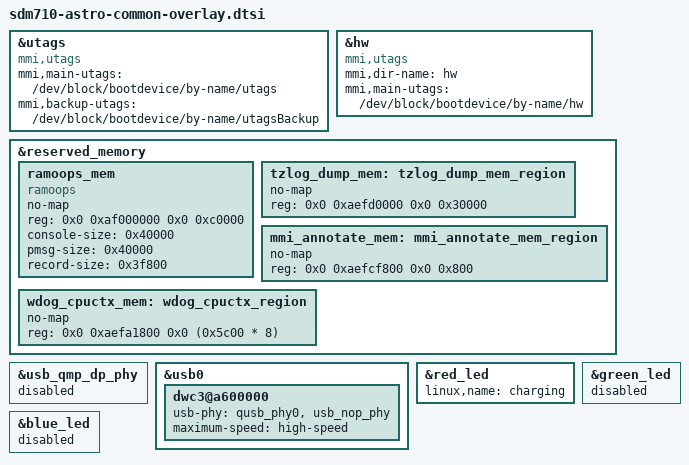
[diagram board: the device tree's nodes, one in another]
/* Copyright (c) 2019, The Linux Foundation. All rights reserved.
 *
 * This program is free software; you can redistribute it and/or modify
 * it under the terms of the GNU General Public License version 2 and
 * only version 2 as published by the Free Software Foundation.
 *
 * This program is distributed in the hope that it will be useful,
 * but WITHOUT ANY WARRANTY; without even the implied warranty of
 * MERCHANTABILITY or FITNESS FOR A PARTICULAR PURPOSE.  See the
 * GNU General Public License for more details.
 */

#include <dt-bindings/clock/qcom,gcc-sdm845.h>
#include <dt-bindings/clock/qcom,camcc-sdm845.h>
#include <dt-bindings/clock/qcom,dispcc-sdm845.h>
#include <dt-bindings/clock/qcom,rpmh.h>
#include <dt-bindings/interrupt-controller/arm-gic.h>

#include "sdm710-moto-common-overlay-base.dtsi"
#include "sdm710-astro-display.dtsi"

&utags {
	compatible = "mmi,utags";
	mmi,main-utags = "/dev/block/bootdevice/by-name/utags";
	mmi,backup-utags = "/dev/block/bootdevice/by-name/utagsBackup";
};

&hw {
	compatible = "mmi,utags";
	mmi,dir-name = "hw";
	mmi,main-utags = "/dev/block/bootdevice/by-name/hw";
};

&reserved_memory {
	ramoops_mem {
		compatible = "ramoops";
		no-map;
		reg = <0x0 0xaf000000 0x0 0xc0000>;
		console-size = <0x40000>;
		pmsg-size = <0x40000>;
		record-size = <0x3f800>;
	};

	tzlog_dump_mem: tzlog_dump_mem_region {
		no-map;
		reg = <0x0 0xaefd0000 0x0 0x30000>;
	};

	mmi_annotate_mem: mmi_annotate_mem_region {
		no-map;
		reg = <0x0 0xaefcf800 0x0 0x800>;
	};

	wdog_cpuctx_mem: wdog_cpuctx_region {
		no-map;
		reg = <0x0 0xaefa1800 0x0 (0x5c00 * 8)>;
	};
};


&usb_qmp_dp_phy {
	status = "disabled";
};

&usb0 {
	dwc3@a600000 {
		usb-phy = <&qusb_phy0>, <&usb_nop_phy>;
		maximum-speed = "high-speed";
	};
};

&red_led {
	status = "ok";
	linux,name = "charging";
};

&green_led {
	status = "disabled";
};

&blue_led {
	status = "disabled";
};

